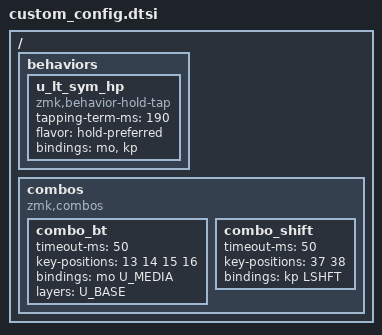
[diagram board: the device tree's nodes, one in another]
// Copyright 2022 Manna Harbour
// https://github.com/manna-harbour/miryoku

#include <dt-bindings/zmk/keys.h>

/ {
  behaviors {
    u_lt_sym_hp: u_lt_sym_hp {
      compatible = "zmk,behavior-hold-tap";
      #binding-cells = <2>;
      tapping-term-ms = <190>;
      flavor = "hold-preferred";
      bindings = <&mo>, <&kp>;
    };
  };

  // Hold A+S+D+F → BT layer (Corne positions; unused outer columns included).
  // Plain 36-key boards: use <10 11 12 13> instead.
  // Middle+inner left thumbs → Shift while held (Corne: 37=middle, 38=inner).
  combos {
    compatible = "zmk,combos";
    combo_bt {
      timeout-ms = <50>;
      key-positions = <13 14 15 16>;
      bindings = <&mo U_MEDIA>;
      layers = <U_BASE>;
    };
    combo_shift {
      timeout-ms = <50>;
      key-positions = <37 38>;
      bindings = <&kp LSHFT>;
    };
  };
};
